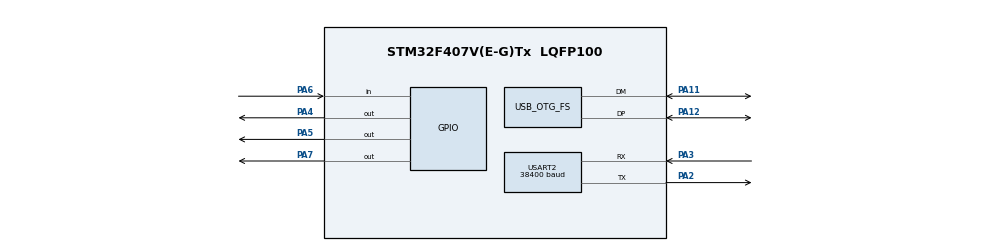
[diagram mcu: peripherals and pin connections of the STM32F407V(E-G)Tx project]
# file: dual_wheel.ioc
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IWDG.Prescaler=IWDG_PRESCALER_256
IWDG.Reload=1250
Mcu.Family=STM32F4
Mcu.Name=STM32F407V(E-G)Tx
Mcu.Package=LQFP100
NVIC.OTG_FS_IRQn=true\:0\:0\:false\:false\:true\:false
NVIC.PriorityGroup=NVIC_PRIORITYGROUP_0
NVIC.USART2_IRQn=true\:0\:0\:false\:false\:true\:true
PA11.Mode=Device_Only
PA11.Signal=USB_OTG_FS_DM
PA12.Mode=Device_Only
PA12.Signal=USB_OTG_FS_DP
PA13.Mode=Trace_Synchro_4bits_SW
PA13.Signal=SYS_JTMS-SWDIO
PA14.Mode=Trace_Synchro_4bits_SW
PA14.Signal=SYS_JTCK-SWCLK
PA2.Mode=Asynchronous
PA2.Signal=USART2_TX
PA3.Mode=Asynchronous
PA3.Signal=USART2_RX
PA4.Signal=GPIO_Output
PA5.Signal=GPIO_Output
PA6.Signal=GPIO_Input
PA7.Signal=GPIO_Output
PC14-OSC32_IN.Mode=LSE-External-Oscillator
PC14-OSC32_IN.Signal=RCC_OSC32_IN
PC15-OSC32_OUT.Mode=LSE-External-Oscillator
PC15-OSC32_OUT.Signal=RCC_OSC32_OUT
PE2.Mode=Trace_Synchro_4bits_SW
PE2.Signal=SYS_TRACECLK
PE3.Mode=Trace_Synchro_4bits_SW
PE3.Signal=SYS_TRACED0
PE4.Mode=Trace_Synchro_4bits_SW
PE4.Signal=SYS_TRACED1
PE5.Mode=Trace_Synchro_4bits_SW
PE5.Signal=SYS_TRACED2
PE6.Mode=Trace_Synchro_4bits_SW
PE6.Signal=SYS_TRACED3
PH0-OSC_IN.Mode=HSE-External-Oscillator
PH0-OSC_IN.Signal=RCC_OSC_IN
PH1-OSC_OUT.Mode=HSE-External-Oscillator
PH1-OSC_OUT.Signal=RCC_OSC_OUT
ProjectManager.HeapSize=0x200
ProjectManager.StackSize=0x400
ProjectManager.TargetToolchain=MDK-ARM V4
RCC.48MHZClocksFreq_Value=48000000
RCC.AHBFreq_Value=168000000
RCC.APB1CLKDivider=RCC_HCLK_DIV4
RCC.APB1Freq_Value=42000000
RCC.APB1TimFreq_Value=84000000
RCC.APB2CLKDivider=RCC_HCLK_DIV4
RCC.APB2Freq_Value=42000000
RCC.APB2TimFreq_Value=84000000
RCC.CortexFreq_Value=168000000
RCC.HCLKFreq_Value=168000000
RCC.HSE_VALUE=8000000
RCC.HSI_VALUE=16000000
RCC.PLLM=4
RCC.PLLN=168
RCC.PLLQ=7
RCC.SYSCLKFreq_VALUE=168000000
RCC.SYSCLKSource=RCC_SYSCLKSOURCE_PLLCLK
RCC.VCOOutputFreq_Value=336000000
USART2.BaudRate=38400
USART2.VirtualMode=VM_ASYNC
USB_DEVICE.CLASS_NAME_FS=HID
USB_DEVICE.VirtualMode-HID_FS=Hid
USB_DEVICE.VirtualModeFS=Hid_FS
USB_OTG_FS.VirtualMode=Device_Only
VP_IWDG_VS_IWDG.Mode=IWDG_Activate
VP_USB_DEVICE_VS_USB_DEVICE_HID_FS.Mode=HID_FS
board=custom

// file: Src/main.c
/**
  ******************************************************************************
  * @file           : main.c
  * @brief          : Main program body
  ******************************************************************************
  * This notice applies to any and all portions of this file
  * that are not between comment pairs USER CODE BEGIN and
  * USER CODE END. Other portions of this file, whether
  * inserted by the user or by software development tools
  * are owned by their respective copyright owners.
  *
  * Copyright (c) 2018 STMicroelectronics International N.V.
  * All rights reserved.
  *
  * Redistribution and use in source and binary forms, with or without
  * modification, are permitted, provided that the following conditions are met:
  *
  * 1. Redistribution of source code must retain the above copyright notice,
  *    this list of conditions and the following disclaimer.
  * 2. Redistributions in binary form must reproduce the above copyright notice,
  *    this list of conditions and the following disclaimer in the documentation
  *    and/or other materials provided with the distribution.
  * 3. Neither the name of STMicroelectronics nor the names of other
  *    contributors to this software may be used to endorse or promote products
  *    derived from this software without specific written permission.
  * 4. This software, including modifications and/or derivative works of this
  *    software, must execute solely and exclusively on microcontroller or
  *    microprocessor devices manufactured by or for STMicroelectronics.
  * 5. Redistribution and use of this software other than as permitted under
  *    this license is void and will automatically terminate your rights under
  *    this license.
  *
  * THIS SOFTWARE IS PROVIDED BY STMICROELECTRONICS AND CONTRIBUTORS "AS IS"
  * AND ANY EXPRESS, IMPLIED OR STATUTORY WARRANTIES, INCLUDING, BUT NOT
  * LIMITED TO, THE IMPLIED WARRANTIES OF MERCHANTABILITY, FITNESS FOR A
  * PARTICULAR PURPOSE AND NON-INFRINGEMENT OF THIRD PARTY INTELLECTUAL PROPERTY
  * RIGHTS ARE DISCLAIMED TO THE FULLEST EXTENT PERMITTED BY LAW. IN NO EVENT
  * SHALL STMICROELECTRONICS OR CONTRIBUTORS BE LIABLE FOR ANY DIRECT, INDIRECT,
  * INCIDENTAL, SPECIAL, EXEMPLARY, OR CONSEQUENTIAL DAMAGES (INCLUDING, BUT NOT
  * LIMITED TO, PROCUREMENT OF SUBSTITUTE GOODS OR SERVICES; LOSS OF USE, DATA,
  * OR PROFITS; OR BUSINESS INTERRUPTION) HOWEVER CAUSED AND ON ANY THEORY OF
  * LIABILITY, WHETHER IN CONTRACT, STRICT LIABILITY, OR TORT (INCLUDING
  * NEGLIGENCE OR OTHERWISE) ARISING IN ANY WAY OUT OF THE USE OF THIS SOFTWARE,
  * EVEN IF ADVISED OF THE POSSIBILITY OF SUCH DAMAGE.
  *
  ******************************************************************************
  */
#include "main.h"
#include "stm32f4xx_hal.h"
#include "iwdg.h"
#include "usart.h"
#include "usb_device.h"
#include "gpio.h"

/* USER CODE BEGIN Includes */
#include "sys_time.h"
#include "sensors.h"
#include "math.h"
#include "attitude.h"
/* USER CODE END Includes */

/* USER CODE BEGIN PV */
/* Private variables ---------------------------------------------------------*/

/* USER CODE END PV */

void SystemClock_Config(void);

/* USER CODE BEGIN PFP */
/* Private function prototypes -----------------------------------------------*/

/* USER CODE END PFP */

int main(void)
{
  /* USER CODE BEGIN 1 */
  static uint64_t lastPrintTime = 0;
  SystemClock_Config();
  /* USER CODE END 1 */

  /* MCU Configuration----------------------------------------------------------*/

  /* Reset of all peripherals, Initializes the Flash interface and the Systick. */
  HAL_Init();

  /* Configure the system clock */
//  SystemClock_Config();

  /* Initialize all configured peripherals */
  MX_GPIO_Init();
  MX_IWDG_Init();
  MX_USART2_UART_Init();
  MX_USB_DEVICE_Init();

  /* Infinite loop */
  /* USER CODE BEGIN WHILE */
  LL_USART_EnableIT_RXNE(USART2);
  BMI160_Init();
  Log("init done\r\n");

  while (1)
  {
    IWDG_Process();
    Attitude_Process();
  /* USER CODE END WHILE */

  /* USER CODE BEGIN 3 */
    if(TimeElapsed(lastPrintTime) > 1000)
    {
      SetToCurTime(&lastPrintTime);
//      Log("%llds\r\n", g_sysTotalTime / 1000);

    }

  }
  /* USER CODE END 3 */

}

void SystemClock_Config(void)
{

  LL_FLASH_SetLatency(LL_FLASH_LATENCY_5);

  if(LL_FLASH_GetLatency() != LL_FLASH_LATENCY_5)
  {
  Error_Handler();
  }
  LL_PWR_SetRegulVoltageScaling(LL_PWR_REGU_VOLTAGE_SCALE1);

  LL_RCC_HSE_Enable();

   /* Wait till HSE is ready */
  while(LL_RCC_HSE_IsReady() != 1)
  {

  }
  LL_RCC_LSI_Enable();

   /* Wait till LSI is ready */
  while(LL_RCC_LSI_IsReady() != 1)
  {

  }
  LL_RCC_PLL_ConfigDomain_SYS(LL_RCC_PLLSOURCE_HSE, LL_RCC_PLLM_DIV_4, 168, LL_RCC_PLLP_DIV_2);

  LL_RCC_PLL_ConfigDomain_48M(LL_RCC_PLLSOURCE_HSE, LL_RCC_PLLM_DIV_4, 168, LL_RCC_PLLQ_DIV_7);

  LL_RCC_PLL_Enable();

   /* Wait till PLL is ready */
  while(LL_RCC_PLL_IsReady() != 1)
  {

  }
  LL_RCC_SetAHBPrescaler(LL_RCC_SYSCLK_DIV_1);

  LL_RCC_SetAPB1Prescaler(LL_RCC_APB1_DIV_4);

  LL_RCC_SetAPB2Prescaler(LL_RCC_APB2_DIV_4);

  LL_RCC_SetSysClkSource(LL_RCC_SYS_CLKSOURCE_PLL);

   /* Wait till System clock is ready */
  while(LL_RCC_GetSysClkSource() != LL_RCC_SYS_CLKSOURCE_STATUS_PLL)
  {

  }
  LL_Init1msTick(168000000);

  LL_SYSTICK_SetClkSource(LL_SYSTICK_CLKSOURCE_HCLK);

  LL_SetSystemCoreClock(168000000);

  /* SysTick_IRQn interrupt configuration */
  NVIC_SetPriority(SysTick_IRQn, NVIC_EncodePriority(NVIC_GetPriorityGrouping(),0, 0));
}

void _Error_Handler(char *file, int line)
{
  while(1)
  {
  }
}

/************************ (C) COPYRIGHT STMicroelectronics *****END OF FILE****/
